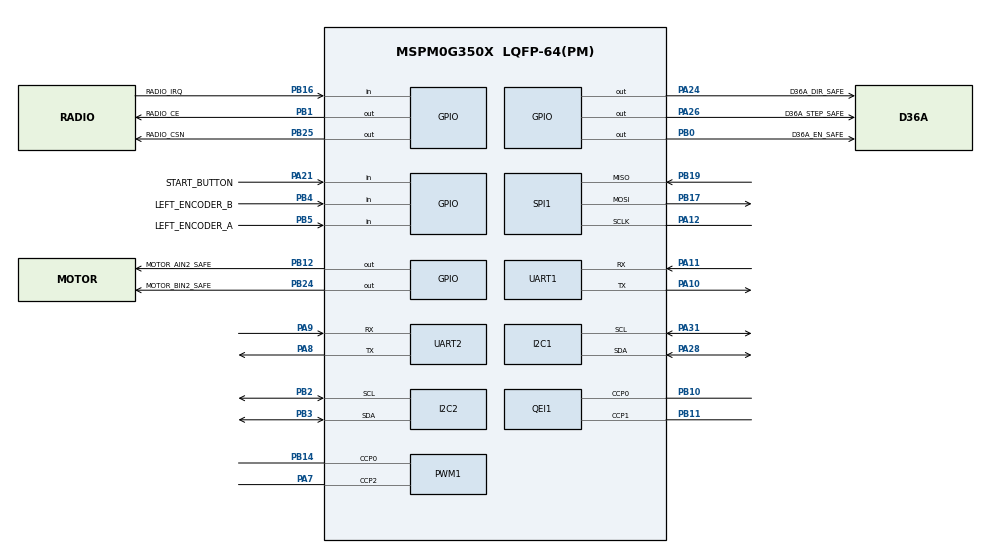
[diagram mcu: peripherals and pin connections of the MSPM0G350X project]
/**
 * @cliArgs --device "MSPM0G350X" --part "Default" --package "LQFP-64(PM)" --product "mspm0_sdk@2.11.00.07"
 * @versions {"tool":"1.26.2+4477"}
 */

const GPIO    = scripting.addModule("/ti/driverlib/GPIO", {}, false);
const UART    = scripting.addModule("/ti/driverlib/UART", {}, false);
const I2C     = scripting.addModule("/ti/driverlib/I2C", {}, false);
const SPI     = scripting.addModule("/ti/driverlib/SPI", {}, false);
const QEI     = scripting.addModule("/ti/driverlib/QEI", {}, false);
const PWM     = scripting.addModule("/ti/driverlib/PWM", {}, false);
const SYSCTL  = scripting.addModule("/ti/driverlib/SYSCTL");

const GPIO1   = GPIO.addInstance();
const UART1   = UART.addInstance();
const UART2   = UART.addInstance();
const I2C1    = I2C.addInstance();
const I2C2    = I2C.addInstance();
const SPI1    = SPI.addInstance();
const QEI1    = QEI.addInstance();
const PWM1    = PWM.addInstance();

/* MotorDriver exclusively owns both DRV8870 PWM and direction outputs. */
GPIO1.$name = "DIAG_GPIO";
GPIO1.associatedPins.create(11);

GPIO1.associatedPins[0].$name        = "MOTOR_AIN2_SAFE";
GPIO1.associatedPins[0].initialValue = "CLEARED";
GPIO1.associatedPins[0].pin.$assign  = "PB12";
GPIO1.associatedPins[1].$name        = "MOTOR_BIN2_SAFE";
GPIO1.associatedPins[1].initialValue = "CLEARED";
GPIO1.associatedPins[1].pin.$assign  = "PB24";

GPIO1.associatedPins[2].$name         = "RADIO_CE";
GPIO1.associatedPins[2].initialValue  = "CLEARED";
GPIO1.associatedPins[2].pin.$assign   = "PB1";
GPIO1.associatedPins[3].$name         = "RADIO_CSN";
GPIO1.associatedPins[3].initialValue  = "SET";
GPIO1.associatedPins[3].pin.$assign   = "PB25";
GPIO1.associatedPins[4].$name         = "RADIO_IRQ";
GPIO1.associatedPins[4].direction     = "INPUT";
GPIO1.associatedPins[4].pin.$assign   = "PB16";
/* User-verified expansion-board KEY2 is PA21; PB21 is unconnected. */
GPIO1.associatedPins[5].$name            = "START_BUTTON";
GPIO1.associatedPins[5].direction        = "INPUT";
GPIO1.associatedPins[5].internalResistor = "PULL_UP";
GPIO1.associatedPins[5].pin.$assign      = "PA21";
GPIO1.associatedPins[6].$name         = "D36A_EN_SAFE";
GPIO1.associatedPins[6].initialValue  = "CLEARED";
GPIO1.associatedPins[6].pin.$assign   = "PB0";
GPIO1.associatedPins[7].$name         = "D36A_DIR_SAFE";
GPIO1.associatedPins[7].initialValue  = "CLEARED";
GPIO1.associatedPins[7].pin.$assign   = "PA24";
GPIO1.associatedPins[8].$name         = "D36A_STEP_SAFE";
GPIO1.associatedPins[8].initialValue  = "CLEARED";
GPIO1.associatedPins[8].pin.$assign   = "PA26";

/* Left wheel software encoder: PB5 rising edge gives 1x count; PB4 is direction. */
GPIO1.associatedPins[9].$name            = "LEFT_ENCODER_B";
GPIO1.associatedPins[9].direction        = "INPUT";
GPIO1.associatedPins[9].internalResistor = "PULL_UP";
GPIO1.associatedPins[9].pin.$assign      = "PB4";
GPIO1.associatedPins[10].$name            = "LEFT_ENCODER_A";
GPIO1.associatedPins[10].direction        = "INPUT";
GPIO1.associatedPins[10].internalResistor = "PULL_UP";
GPIO1.associatedPins[10].interruptEn      = true;
GPIO1.associatedPins[10].polarity         = "RISE";
GPIO1.associatedPins[10].pin.$assign      = "PB5";

UART1.$name                    = "DIAG_UART";
UART1.enableFIFO               = true;
UART1.enableDMARX              = false;
UART1.enableDMATX              = false;
UART1.targetBaudRate           = 115200;
UART1.rxFifoThreshold          = "DL_UART_RX_FIFO_LEVEL_ONE_ENTRY";
UART1.enabledInterrupts        = ["RX"];
UART1.peripheral.$assign       = "UART0";
UART1.peripheral.rxPin.$assign = "PA11";
UART1.peripheral.txPin.$assign = "PA10";

/* K230 sends fixed 14-byte binary frames to MSPM0 through UART1 RX. */
UART2.$name                    = "K230_UART";
UART2.enableFIFO               = true;
UART2.enableDMARX              = false;
UART2.enableDMATX              = false;
UART2.targetBaudRate           = 115200;
UART2.rxFifoThreshold          = "DL_UART_RX_FIFO_LEVEL_ONE_ENTRY";
UART2.enabledInterrupts        = ["RX"];
UART2.peripheral.$assign       = "UART1";
UART2.peripheral.rxPin.$assign = "PA9";
UART2.peripheral.txPin.$assign = "PA8";

I2C1.$name                     = "LINE_I2C";
I2C1.basicEnableController     = true;
I2C1.basicControllerBusSpeed   = 100000;
I2C1.advAnalogGlitchFilter     = "DISABLED";
I2C1.peripheral.$assign        = "I2C0";
I2C1.peripheral.sdaPin.$assign = "PA28";
I2C1.peripheral.sclPin.$assign = "PA31";

I2C2.$name                     = "OLED_I2C";
I2C2.basicEnableController     = true;
I2C2.basicControllerBusSpeed   = 100000;
I2C2.advAnalogGlitchFilter     = "DISABLED";
I2C2.peripheral.$assign        = "I2C1";
I2C2.peripheral.sdaPin.$assign = "PB3";
I2C2.peripheral.sclPin.$assign = "PB2";

/* PB25 is software CSN so complete nRF command frames stay selected. */
SPI1.$name                      = "RADIO_SPI";
SPI1.targetBitRate              = 500000;
SPI1.chipSelect                 = [];
SPI1.frameFormat                = "MOTO3";
SPI1.peripheral.$assign         = "SPI0";
SPI1.peripheral.sclkPin.$assign = "PA12";
SPI1.peripheral.mosiPin.$assign = "PB17";
SPI1.peripheral.misoPin.$assign = "PB19";

QEI1.$name                      = "RIGHT_QEI";
QEI1.interrupts                 = ["DC_EVENT"];
QEI1.timerStartTimer            = false;
QEI1.peripheral.$assign         = "TIMG8";
QEI1.peripheral.ccp0Pin.$assign = "PB10";
QEI1.peripheral.ccp1Pin.$assign = "PB11";

/* 20 kHz edge-aligned PWM on the frozen TIMA0 motor channels. */
PWM1.$name                         = "MOTOR_PWM";
PWM1.timerStartTimer               = false;
PWM1.timerCount                    = 1600;
PWM1.ccIndex                       = [0,2];
PWM1.peripheral.$assign            = "TIMA0";
PWM1.peripheral.ccp0Pin.$assign    = "PB14";
PWM1.peripheral.ccp2Pin.$assign    = "PA7";
PWM1.PWM_CHANNEL_0.$name           = "ti_driverlib_pwm_PWMTimerCC0";
PWM1.PWM_CHANNEL_0.dutyCycle       = 0;
PWM1.PWM_CHANNEL_2.$name           = "ti_driverlib_pwm_PWMTimerCC6";
PWM1.PWM_CHANNEL_2.dutyCycle       = 0;

const Board = scripting.addModule("/ti/driverlib/Board", {}, false);
SYSCTL.forceDefaultClkConfig = true;
SYSCTL.clockTreeEn           = true;
